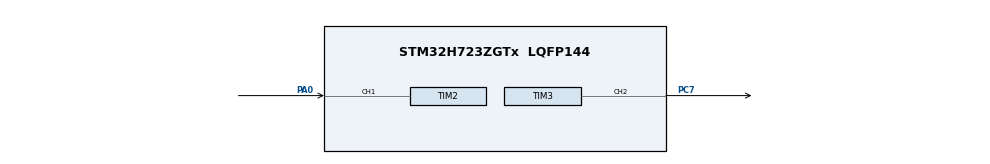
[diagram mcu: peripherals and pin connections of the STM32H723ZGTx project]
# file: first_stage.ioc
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FREERTOS.Tasks01=defaultTask,0,128,StartDefaultTask,Default,NULL,Dynamic,NULL,NULL
FREERTOS.configUSE_NEWLIB_REENTRANT=1
Mcu.Family=STM32H7
Mcu.Name=STM32H723ZGTx
Mcu.Package=LQFP144
NVIC.PriorityGroup=NVIC_PRIORITYGROUP_4
NVIC.TIM1_UP_IRQn=true\:15\:0\:false\:false\:true\:false\:false\:true\:true
NVIC.TIM2_IRQn=true\:5\:0\:false\:false\:true\:true\:true\:true\:true
NVIC.TimeBase=TIM1_UP_IRQn
NVIC.TimeBaseIP=TIM1
PA0.Signal=S_TIM2_CH1_ETR
PC7.Signal=S_TIM3_CH2
ProjectManager.HeapSize=0x200
ProjectManager.StackSize=0x400
ProjectManager.TargetToolchain=STM32CubeIDE
RCC.ADCFreq_Value=129000000
RCC.APB1Freq_Value=137500000
RCC.APB2Freq_Value=137500000
RCC.APB3Freq_Value=137500000
RCC.APB4Freq_Value=137500000
RCC.CortexFreq_Value=550000000
RCC.D1PPRE=RCC_APB3_DIV2
RCC.D2PPRE1=RCC_APB1_DIV2
RCC.D2PPRE2=RCC_APB2_DIV2
RCC.D3PPRE=RCC_APB4_DIV2
RCC.DIVM1=4
RCC.DIVN1=34
RCC.DIVP1=1
RCC.HCLKFreq_Value=275000000
RCC.HPRE=RCC_HCLK_DIV2
RCC.PLL2FRACN=0
RCC.PLL3FRACN=0
RCC.PLLFRACN=3072
RCC.SYSCLKFreq_VALUE=550000000
RCC.SYSCLKSource=RCC_SYSCLKSOURCE_PLLCLK
RCC.USBFreq_Value=275000000
SH.S_TIM2_CH1_ETR.0=TIM2_CH1,Input_Capture1_from_TI1
SH.S_TIM3_CH2.0=TIM3_CH2,PWM Generation2 CH2
TIM2.Channel-Input_Capture1_from_TI1=TIM_CHANNEL_1
TIM2.Prescaler=137 - 1
TIM3.Channel-PWM\ Generation2\ CH2=TIM_CHANNEL_2
TIM3.Period=50000
TIM3.Prescaler=550 - 1
TIM3.Pulse-PWM\ Generation2\ CH2=5
VP_FREERTOS_VS_CMSIS_V1.Mode=CMSIS_V1
VP_SYS_VS_tim1.Mode=TIM1
board=custom

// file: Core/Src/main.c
/* USER CODE BEGIN Header */
/**
  ******************************************************************************
  * @file           : main.c
  * @brief          : Main program body
  ******************************************************************************
  * @attention
  *
  * Copyright (c) 2023 STMicroelectronics.
  * All rights reserved.
  *
  * This software is licensed under terms that can be found in the LICENSE file
  * in the root directory of this software component.
  * If no LICENSE file comes with this software, it is provided AS-IS.
  *
  ******************************************************************************
  */
/* USER CODE END Header */
#include "main.h"
#include "cmsis_os.h"
#include "tim.h"
#include "gpio.h"

void SystemClock_Config(void);
void MX_FREERTOS_Init(void);

int main(void)
{

  /* MCU Configuration--------------------------------------------------------*/

  /* Reset of all peripherals, Initializes the Flash interface and the Systick. */
  HAL_Init();

  /* Configure the system clock */
  SystemClock_Config();

  /* Initialize all configured peripherals */
  MX_GPIO_Init();
  MX_TIM3_Init();
  MX_TIM2_Init();
  /* USER CODE BEGIN 2 */
  HAL_TIM_PWM_Start(&htim3, TIM_CHANNEL_2);
  HAL_TIM_IC_Start_IT(&htim2, TIM_CHANNEL_1);

  /* USER CODE END 2 */

  /* Call init function for freertos objects (in freertos.c) */
  MX_FREERTOS_Init();

  /* Start scheduler */
  osKernelStart();

  /* We should never get here as control is now taken by the scheduler */
  /* Infinite loop */
  while (1)
  {

  }
}

void SystemClock_Config(void)
{
  RCC_OscInitTypeDef RCC_OscInitStruct = {0};
  RCC_ClkInitTypeDef RCC_ClkInitStruct = {0};

  /** Supply configuration update enable
  */
  HAL_PWREx_ConfigSupply(PWR_LDO_SUPPLY);

  /** Configure the main internal regulator output voltage
  */
  __HAL_PWR_VOLTAGESCALING_CONFIG(PWR_REGULATOR_VOLTAGE_SCALE0);

  while(!__HAL_PWR_GET_FLAG(PWR_FLAG_VOSRDY)) {}

  /** Initializes the RCC Oscillators according to the specified parameters
  * in the RCC_OscInitTypeDef structure.
  */
  RCC_OscInitStruct.OscillatorType = RCC_OSCILLATORTYPE_HSI;
  RCC_OscInitStruct.HSIState = RCC_HSI_DIV1;
  RCC_OscInitStruct.HSICalibrationValue = RCC_HSICALIBRATION_DEFAULT;
  RCC_OscInitStruct.PLL.PLLState = RCC_PLL_ON;
  RCC_OscInitStruct.PLL.PLLSource = RCC_PLLSOURCE_HSI;
  RCC_OscInitStruct.PLL.PLLM = 4;
  RCC_OscInitStruct.PLL.PLLN = 34;
  RCC_OscInitStruct.PLL.PLLP = 1;
  RCC_OscInitStruct.PLL.PLLQ = 2;
  RCC_OscInitStruct.PLL.PLLR = 2;
  RCC_OscInitStruct.PLL.PLLRGE = RCC_PLL1VCIRANGE_3;
  RCC_OscInitStruct.PLL.PLLVCOSEL = RCC_PLL1VCOWIDE;
  RCC_OscInitStruct.PLL.PLLFRACN = 3072;
  if (HAL_RCC_OscConfig(&RCC_OscInitStruct) != HAL_OK)
  {
    Error_Handler();
  }

  /** Initializes the CPU, AHB and APB buses clocks
  */
  RCC_ClkInitStruct.ClockType = RCC_CLOCKTYPE_HCLK|RCC_CLOCKTYPE_SYSCLK
                              |RCC_CLOCKTYPE_PCLK1|RCC_CLOCKTYPE_PCLK2
                              |RCC_CLOCKTYPE_D3PCLK1|RCC_CLOCKTYPE_D1PCLK1;
  RCC_ClkInitStruct.SYSCLKSource = RCC_SYSCLKSOURCE_PLLCLK;
  RCC_ClkInitStruct.SYSCLKDivider = RCC_SYSCLK_DIV1;
  RCC_ClkInitStruct.AHBCLKDivider = RCC_HCLK_DIV2;
  RCC_ClkInitStruct.APB3CLKDivider = RCC_APB3_DIV2;
  RCC_ClkInitStruct.APB1CLKDivider = RCC_APB1_DIV2;
  RCC_ClkInitStruct.APB2CLKDivider = RCC_APB2_DIV2;
  RCC_ClkInitStruct.APB4CLKDivider = RCC_APB4_DIV2;

  if (HAL_RCC_ClockConfig(&RCC_ClkInitStruct, FLASH_LATENCY_3) != HAL_OK)
  {
    Error_Handler();
  }
}

void HAL_TIM_PeriodElapsedCallback(TIM_HandleTypeDef *htim)
{
  if (htim->Instance == TIM1) {
    HAL_IncTick();
  }
}

void Error_Handler(void)
{
  __disable_irq();
  while (1)
  {
  }
}
